# I2C1 register map
Registers from a debugger description file.
Registers are 32-bit, read-only, no defined reset value unless marked. A register's access mark holds for its fields unless they carry their own. Addresses are absolute; registers are grouped by the start of their names; lines under a group give offsets from that group; [hi:lo] are bit positions; {n}, {i} and the like mark numbered series; 'fields as' and 'values as' point back to an identical list; <NAME> marks a mode.

## I2C1
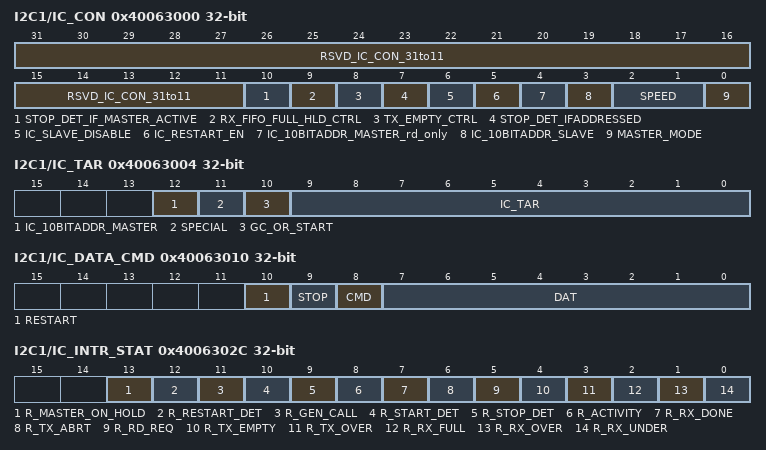
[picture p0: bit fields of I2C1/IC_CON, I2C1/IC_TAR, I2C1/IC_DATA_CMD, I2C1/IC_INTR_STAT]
0x40063000 I2C1/IC_CON access not given
  [31:11] RSVD_IC_CON_31to11, [10] STOP_DET_IF_MASTER_ACTIVE, [9] RX_FIFO_FULL_HLD_CTRL, [8] TX_EMPTY_CTRL, [7] STOP_DET_IFADDRESSED, [6] IC_SLAVE_DISABLE, [5] IC_RESTART_EN, [4] IC_10BITADDR_MASTER_rd_only, [3] IC_10BITADDR_SLAVE, [2:1] SPEED, [0] MASTER_MODE
0x40063004 I2C1/IC_TAR access not given
  [12] IC_10BITADDR_MASTER, [11] SPECIAL, [10] GC_OR_START, [9:0] IC_TAR
0x40063008 I2C1/IC_SAR access not given
  [9:0] IC_SAR
0x40063010 I2C1/IC_DATA_CMD access not given
  [10] RESTART, [9] STOP, [8] CMD, [7:0] DAT
0x40063014 I2C1/IC_SS_SCL_HCNT access not given
  [15:0] IC_SS_SCL_HCNT
0x40063018 I2C1/IC_SS_SCL_LCNT access not given
  [15:0] IC_SS_SCL_LCNT
0x4006301C I2C1/IC_FS_SCL_HCNT access not given
  [15:0] IC_FS_SCL_HCNT
0x40063020 I2C1/IC_FS_SCL_LCNT access not given
  [15:0] IC_FS_SCL_LCNT
0x4006302C I2C1/IC_INTR_STAT
  [13] R_MASTER_ON_HOLD, [12] R_RESTART_DET, [11] R_GEN_CALL, [10] R_START_DET, [9] R_STOP_DET, [8] R_ACTIVITY, [7] R_RX_DONE, [6] R_TX_ABRT, [5] R_RD_REQ, [4] R_TX_EMPTY, [3] R_TX_OVER, [2] R_RX_FULL, [1] R_RX_OVER, [0] R_RX_UNDER
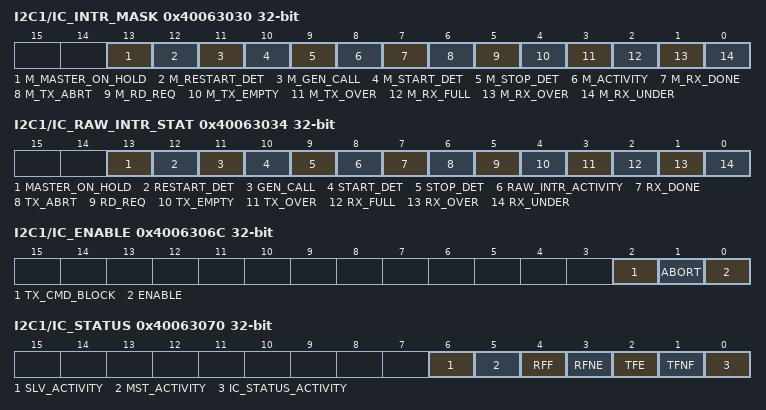
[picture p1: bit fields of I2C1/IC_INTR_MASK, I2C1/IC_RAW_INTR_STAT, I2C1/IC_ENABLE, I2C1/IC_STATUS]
0x40063030 I2C1/IC_INTR_MASK access not given
  [13] M_MASTER_ON_HOLD, [12] M_RESTART_DET, [11] M_GEN_CALL, [10] M_START_DET, [9] M_STOP_DET, [8] M_ACTIVITY, [7] M_RX_DONE, [6] M_TX_ABRT, [5] M_RD_REQ, [4] M_TX_EMPTY, [3] M_TX_OVER, [2] M_RX_FULL, [1] M_RX_OVER, [0] M_RX_UNDER
0x40063034 I2C1/IC_RAW_INTR_STAT
  [13] MASTER_ON_HOLD, [12] RESTART_DET, [11] GEN_CALL, [10] START_DET, [9] STOP_DET, [8] RAW_INTR_ACTIVITY, [7] RX_DONE, [6] TX_ABRT, [5] RD_REQ, [4] TX_EMPTY, [3] TX_OVER, [2] RX_FULL, [1] RX_OVER, [0] RX_UNDER
0x40063038 I2C1/IC_RX_TL access not given
  [7:0] RX_TL
0x4006303C I2C1/IC_TX_TL access not given
  [7:0] TX_TL
0x40063040 I2C1/IC_CLR_INTR
  [0] CLR_INTR
0x40063044 I2C1/IC_CLR_RX_UNDER
  [0] CLR_RX_UNDER
0x40063048 I2C1/IC_CLR_RX_OVER
  [0] CLR_RX_OVER
0x4006304C I2C1/IC_CLR_TX_OVER
  [0] CLR_TX_OVER
0x40063050 I2C1/IC_CLR_RD_REQ
  [0] CLR_RD_REQ
0x40063054 I2C1/IC_CLR_TX_ABRT
  [0] CLR_TX_ABRT
0x40063058 I2C1/IC_CLR_RX_DONE
  [0] CLR_RX_DONE
0x4006305C I2C1/IC_CLR_ACTIVITY
  [0] CLR_ACTIVITY
0x40063060 I2C1/IC_CLR_STOP_DET
  [0] CLR_STOP_DET
0x40063064 I2C1/IC_CLR_START_DET
  [0] CLR_START_DET
0x40063068 I2C1/IC_CLR_GEN_CALL
  [0] CLR_GEN_CALL
0x4006306C I2C1/IC_ENABLE access not given
  [2] TX_CMD_BLOCK, [1] ABORT, [0] ENABLE
0x40063070 I2C1/IC_STATUS
  [6] SLV_ACTIVITY, [5] MST_ACTIVITY, [4] RFF, [3] RFNE, [2] TFE, [1] TFNF, [0] IC_STATUS_ACTIVITY
0x40063074 I2C1/IC_TXFLR
  [3:0] TXFLR
0x40063078 I2C1/IC_RXFLR
  [3:0] RXFLR
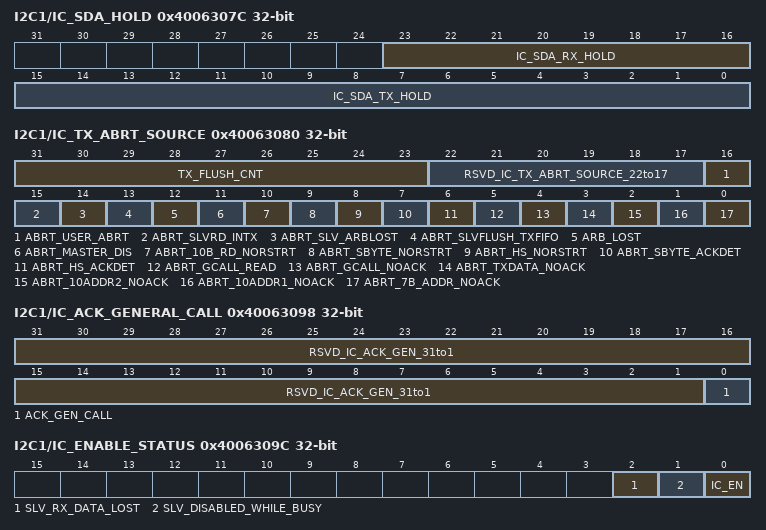
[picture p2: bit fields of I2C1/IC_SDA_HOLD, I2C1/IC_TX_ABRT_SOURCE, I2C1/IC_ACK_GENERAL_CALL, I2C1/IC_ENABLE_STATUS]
0x4006307C I2C1/IC_SDA_HOLD access not given
  [23:16] IC_SDA_RX_HOLD, [15:0] IC_SDA_TX_HOLD
0x40063080 I2C1/IC_TX_ABRT_SOURCE
  [31:23] TX_FLUSH_CNT, [22:17] RSVD_IC_TX_ABRT_SOURCE_22to17, [16] ABRT_USER_ABRT, [15] ABRT_SLVRD_INTX, [14] ABRT_SLV_ARBLOST, [13] ABRT_SLVFLUSH_TXFIFO, [12] ARB_LOST, [11] ABRT_MASTER_DIS, [10] ABRT_10B_RD_NORSTRT, [9] ABRT_SBYTE_NORSTRT, [8] ABRT_HS_NORSTRT, [7] ABRT_SBYTE_ACKDET, [6] ABRT_HS_ACKDET, [5] ABRT_GCALL_READ, [4] ABRT_GCALL_NOACK, [3] ABRT_TXDATA_NOACK, [2] ABRT_10ADDR2_NOACK, [1] ABRT_10ADDR1_NOACK, [0] ABRT_7B_ADDR_NOACK
0x40063084 I2C1/IC_SLV_DATA_NACK_ONLY access not given
  [0] NACK
0x40063094 I2C1/IC_SDA_SETUP access not given
  [7:0] SDA_SETUP
0x40063098 I2C1/IC_ACK_GENERAL_CALL access not given
  [31:1] RSVD_IC_ACK_GEN_31to1, [0] ACK_GEN_CALL
0x4006309C I2C1/IC_ENABLE_STATUS
  [2] SLV_RX_DATA_LOST, [1] SLV_DISABLED_WHILE_BUSY, [0] IC_EN
0x400630A0 I2C1/IC_FS_SPKLEN access not given
  [7:0] IC_FS_SPKLEN
0x400630A8 I2C1/IC_CLR_RESTART_DET
  [0] CLR_RESTART_DET
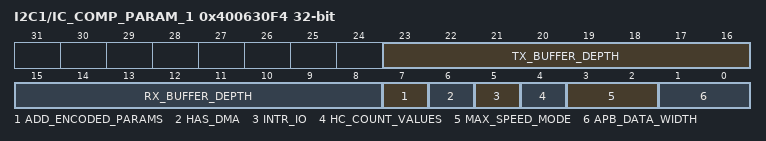
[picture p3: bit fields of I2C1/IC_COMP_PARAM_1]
0x400630F4 I2C1/IC_COMP_PARAM_1
  [23:16] TX_BUFFER_DEPTH, [15:8] RX_BUFFER_DEPTH, [7] ADD_ENCODED_PARAMS, [6] HAS_DMA, [5] INTR_IO, [4] HC_COUNT_VALUES, [3:2] MAX_SPEED_MODE, [1:0] APB_DATA_WIDTH
0x400630F8 I2C1/IC_COMP_VERSION
0x400630FC I2C1/IC_COMP_TYPE
